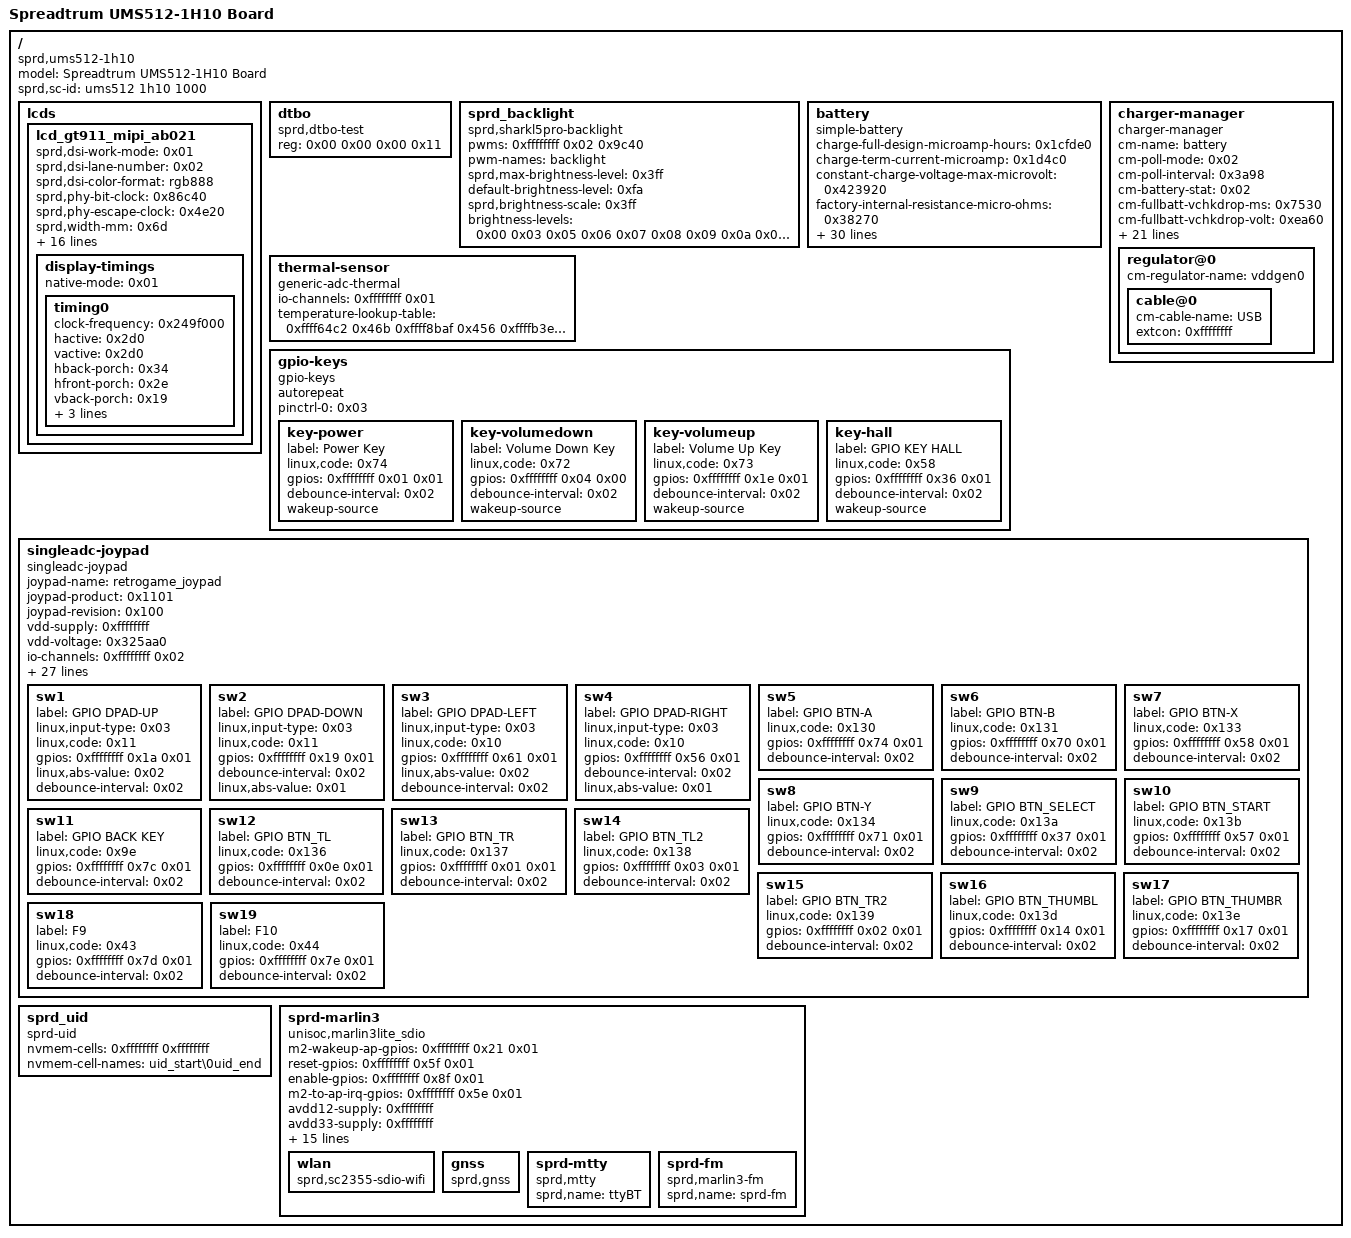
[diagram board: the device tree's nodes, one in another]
/dts-v1/;

/ {
	model = "Spreadtrum UMS512-1H10 Board";
	compatible = "sprd,ums512-1h10\0sprd,ums512";
	sprd,sc-id = "ums512 1h10 1000";

	fragment {
		target-path = "/";

		__overlay__ {
			#address-cells = <0x02>;
			#size-cells = <0x02>;

			lcds {

				lcd_gt911_mipi_ab021 {
					sprd,dsi-work-mode = <0x01>;
					sprd,dsi-lane-number = <0x02>;
					sprd,dsi-color-format = "rgb888";
					sprd,phy-bit-clock = <0x86c40>;
					sprd,phy-escape-clock = <0x4e20>;
					sprd,width-mm = <0x6d>;
					sprd,height-mm = <0x3e>;
					sprd,esd-check-enable = <0x00>;
					sprd,esd-check-mode = <0x03>;
					sprd,esd-check-period = <0x3e8>;
					sprd,esd-check-register = <0x0a>;
					sprd,esd-check-value = <0x9c>;
					sprd,reset-on-sequence = <0x01 0x32 0x00 0x32 0x01 0x78>;
					sprd,reset-off-sequence = <0x00 0x05>;
					sprd,use-dcs-write;
					sprd,initial-command = <0x29000002 0xff302900 0x2ff52 0x29000002 0xff012900 0x2e300 0x29000002 0x250a2900 0x2285f 0x29000002 0x29c22900 0x22acf 0x29000002 0x30582900 0x2379c 0x29000002 0x38a72900 0x2391f 0x29000002 0x44002900 0x2493c 0x29000002 0x59fe2900 0x25c00 0x29000002 0x80202900 0x29177 0x29000002 0x92772900 0x2a055 0x29000002 0xa1502900 0x2a358 0x29000002 0xa49c2900 0x2a702 0x29000002 0xa8012900 0x2a901 0x29000002 0xaafc2900 0x2ab28 0x29000002 0xac062900 0x2ad06 0x29000002 0xae062900 0x2af03 0x29000002 0xb0082900 0x2b126 0x29000002 0xb2282900 0x2b328 0x29000002 0xb4032900 0x2b508 0x29000002 0xb6262900 0x2b708 0x29000002 0xb8262900 0x2c000 0x29000002 0xc1002900 0x2c200 0x29000002 0xc30f2900 0x2ff30 0x29000002 0xff522900 0x2ff02 0x29000002 0xb0002900 0x2b10f 0x29000002 0xb2122900 0x2b332 0x29000002 0xb4242900 0x2b53f 0x29000002 0xb6252900 0x2b73f 0x29000002 0xb80e2900 0x2b906 0x29000002 0xba112900 0x2bb10 0x29000002 0xbc102900 0x2bd13 0x29000002 0xbe1b2900 0x2bf10 0x29000002 0xc0172900 0x2c108 0x29000002 0xd0002900 0x2d10d 0x29000002 0xd2122900 0x2d32a 0x29000002 0xd42e2900 0x2d53f 0x29000002 0xd6292900 0x2d743 0x29000002 0xd8102900 0x2d908 0x29000002 0xda132900 0x2db10 0x29000002 0xdc122900 0x2dd13 0x29000002 0xde1f2900 0x2df1a 0x29000002 0xe01f2900 0x2e10a 0x29000002 0xff302900 0x2ff52 0x29000002 0xff032900 0x20451 0x29000002 0x5c02900 0x206c0 0x29000002 0x8862900 0x20987 0x29000002 0xa842900 0x20b85 0x29000002 0x28332900 0x22933 0x29000002 0x2aeb2900 0x22bea 0x29000002 0x2ced2900 0x22dec 0x29000002 0x34812900 0x23553 0x29000002 0x37232900 0x24084 0x29000002 0x41852900 0x24282 0x29000002 0x43832900 0x24433 0x29000002 0x45ea2900 0x246e9 0x29000002 0x47332900 0x248ec 0x29000002 0x49eb2900 0x25080 0x29000002 0x51812900 0x25202 0x29000002 0x53012900 0x25433 0x29000002 0x55ee2900 0x256ed 0x29000002 0x57332900 0x258f0 0x29000002 0x59ef2900 0x28000 0x29000002 0x81012900 0x28206 0x29000002 0x83072900 0x28404 0x29000002 0x85052900 0x29203 0x29000002 0x93022900 0x29600 0x29000002 0x97012900 0x29806 0x29000002 0x99072900 0x29a04 0x29000002 0x9b052900 0x2a803 0x29000002 0xa9022900 0x2ff30 0x29000002 0xff522900 0x2ff00 0x29000002 0x36012900 0x2532c 0x5c80002 0x11000564 0x22900>;
					sprd,sleep-in-command = [13 0a 00 01 28 13 78 00 01 10];
					sprd,sleep-out-command = [13 78 00 01 11 13 32 00 01 29];
					phandle = <0x14>;

					display-timings {
						native-mode = <0x01>;

						timing0 {
							clock-frequency = <0x249f000>;
							hactive = <0x2d0>;
							vactive = <0x2d0>;
							hback-porch = <0x34>;
							hfront-porch = <0x2e>;
							vback-porch = <0x19>;
							vfront-porch = <0x1e>;
							hsync-len = <0x02>;
							vsync-len = <0x02>;
							phandle = <0x01>;
						};
					};
				};
			};

			dtbo {
				compatible = "sprd,dtbo-test";
				reg = <0x00 0x00 0x00 0x11>;
				phandle = <0x15>;
			};

			sprd_backlight {
				compatible = "sprd,sharkl5pro-backlight";
				pwms = <0xffffffff 0x02 0x9c40>;
				pwm-names = "backlight";
				sprd,max-brightness-level = <0x3ff>;
				default-brightness-level = <0xfa>;
				sprd,brightness-scale = <0x3ff>;
				brightness-levels = <0x00 0x03 0x05 0x06 0x07 0x08 0x09 0x0a 0x0c 0x0d 0x0e 0x0f 0x10 0x11 0x13 0x14 0x15 0x16 0x17 0x18 0x1a 0x1b 0x1c 0x1d 0x1e 0x1f 0x20 0x22 0x24 0x26 0x29 0x2b 0x2d 0x30 0x32 0x34 0x35 0x38 0x3a 0x3c 0x3f 0x41 0x43 0x46 0x48 0x4a 0x4d 0x4f 0x51 0x54 0x56 0x58 0x5a 0x5d 0x5f 0x61 0x64 0x66 0x68 0x6b 0x6d 0x6f 0x72 0x74 0x76 0x79 0x7b 0x7d 0x80 0x82 0x84 0x87 0x89 0x8b 0x8e 0x90 0x92 0x94 0x97 0x99 0x9b 0x9e 0xa0 0xa2 0xa5 0xa7 0xa9 0xac 0xae 0xb0 0xb3 0xb5 0xb7 0xba 0xbc 0xbe 0xc1 0xc4 0xc8 0xcb 0xce 0xd2 0xd5 0xd9 0xdc 0xe0 0xe3 0xe7 0xea 0xee 0xf1 0xf5 0xf8 0xfc 0xff 0x103 0x106 0x10a 0x10d 0x111 0x114 0x118 0x11b 0x11f 0x122 0x125 0x129 0x12c 0x130 0x133 0x137 0x13a 0x13e 0x141 0x145 0x148 0x14c 0x150 0x155 0x15a 0x15e 0x163 0x168 0x16c 0x171 0x176 0x17a 0x17f 0x183 0x188 0x18d 0x191 0x196 0x19b 0x19f 0x1a4 0x1a9 0x1ad 0x1b2 0x1b6 0x1bb 0x1c0 0x1c4 0x1c9 0x1ce 0x1d2 0x1d7 0x1dc 0x1e0 0x1e5 0x1ea 0x1ee 0x1f3 0x1f7 0x1fc 0x201 0x205 0x20b 0x211 0x217 0x21d 0x222 0x228 0x22e 0x234 0x23a 0x23f 0x245 0x24b 0x251 0x257 0x25c 0x262 0x268 0x26e 0x274 0x279 0x27f 0x285 0x28b 0x291 0x296 0x29c 0x2a2 0x2a8 0x2ae 0x2b3 0x2b9 0x2bf 0x2c5 0x2cb 0x2d0 0x2d6 0x2dc 0x2e2 0x2e8 0x2ed 0x2f4 0x2fb 0x302 0x309 0x310 0x317 0x31e 0x325 0x32c 0x333 0x33a 0x341 0x348 0x34f 0x356 0x35d 0x364 0x36b 0x372 0x379 0x380 0x386 0x38d 0x394 0x39b 0x3a2 0x3a9 0x3b0 0x3b7 0x3be 0x3c5 0x3cc 0x3d3 0x3da 0x3e1 0x3e8 0x3ef 0x3f6 0x3ff>;
				phandle = <0x07>;
			};

			battery {
				compatible = "simple-battery";
				charge-full-design-microamp-hours = <0x1cfde0>;
				charge-term-current-microamp = <0x1d4c0>;
				constant-charge-voltage-max-microvolt = <0x423920>;
				factory-internal-resistance-micro-ohms = <0x38270>;
				voltage-min-design-microvolt = <0x340850>;
				fullbatt-voltage = <0x422598>;
				fullbatt-current = <0x4e200>;
				fullbatt-track-end-vol = <0x422598>;
				fullbatt-track-end-cur = <0x50910>;
				first-calib-voltage = <0x349cc0>;
				first-calib-capacity = <0x32>;
				ocv-capacity-celsius = <0x19>;
				ocv-capacity-table-0 = <0x423150 0x64 0x40be38 0x5f 0x3feb48 0x5a 0x3f3798 0x55 0x3e9770 0x50 0x3dd038 0x4b 0x3d10d0 0x46 0x3c64f0 0x41 0x3b8648 0x3c 0x3a9800 0x37 0x39bd40 0x32 0x391930 0x2d 0x3880d8 0x28 0x380ba8 0x23 0x37c940 0x1e 0x374470 0x19 0x36daf8 0x14 0x364a70 0x0f 0x35c1b8 0x0a 0x3540d0 0x05 0x341020 0x00>;
				voltage-temp-table = <0x10b558 0x320 0xf0b90 0x352 0xd65b0 0x384 0xbd358 0x3b6 0xa5870 0x3e8 0x900b0 0x41a 0x7c830 0x44c 0x6b6c0 0x47e 0x5c490 0x4b0 0x4f1a0 0x4e2 0x43df0 0x514 0x3a1b0 0x546 0x31ce0 0x578 0x2ab98 0x5aa 0x249f0 0x5dc 0x1f7e8 0x60e 0x1b198 0x640 0x17700 0x672>;
				capacity-temp-table = <0x2d 0x64 0x19 0x64 0x0a 0x62 0x00 0x5d 0xfffffff6 0x55 0xffffffec 0x40>;
				resistance-temp-table = <0x2d 0x62 0x19 0x61 0x0a 0x61 0x00 0x61 0xfffffff6 0x62 0xffffffec 0x62>;
				charge-sdp-current-microamp = <0x7a120 0x7a120>;
				charge-dcp-current-microamp = <0x1e8480 0x2dc6c0>;
				charge-cdp-current-microamp = <0x1e8480 0x1e8480>;
				charge-unknown-current-microamp = <0x118c30 0x118c30>;
				dcp-jeita-temp-table = <0x3e8 0x406 0x00 0x423920 0x47e 0x49c 0xf4240 0x423920 0x5aa 0x58c 0x1e8480 0x423920 0x640 0x622 0xaae60 0x3e8fa0>;
				sdp-jeita-temp-table = <0x3e8 0x406 0x00 0x423920 0x47e 0x49c 0x7a120 0x423920 0x5aa 0x58c 0x1e8480 0x423920 0x640 0x622 0x7a120 0x3e8fa0>;
				cdp-jeita-temp-table = <0x3e8 0x406 0x00 0x423920 0x47e 0x49c 0x16e360 0x423920 0x5aa 0x58c 0x1e8480 0x423920 0x640 0x622 0xaae60 0x3e8fa0>;
				unknown-jeita-temp-table = <0x3e8 0x406 0x00 0x423920 0x47e 0x49c 0x7a120 0x423920 0x5aa 0x58c 0x7a120 0x423920 0x640 0x622 0x7a120 0x3e8fa0>;
				force-jeita-status = <0x02>;
				phandle = <0x02>;
			};

			charger-manager {
				compatible = "charger-manager";
				cm-name = "battery";
				cm-poll-mode = <0x02>;
				cm-poll-interval = <0x3a98>;
				cm-battery-stat = <0x02>;
				cm-fullbatt-vchkdrop-ms = <0x7530>;
				cm-fullbatt-vchkdrop-volt = <0xea60>;
				cm-fullbatt-capacity = <0x64>;
				cm-fullbatt-soc = <0x64>;
				cm-num-chargers = <0x01>;
				cm-chargers = "aw32257-charger";
				cm-fuel-gauge = "sc27xx-fgu";
				cm-battery-cold = <0xc8>;
				cm-battery-cold-in-minus;
				cm-battery-hot = <0x320>;
				cm-battery-temp-diff = <0x64>;
				cm-charging-max = <0x1499700>;
				cm-discharging-max = <0x2932e0>;
				cm-wdt-interval = <0x3c>;
				cm-shutdown-voltage = <0x2f4d60>;
				cm-tickle-time-out = <0x12c>;
				cm-one-cap-time = <0x1e>;
				cm-thermal-zone = "board-thmzone";
				cm-charge-voltage-max = <0x632ea0>;
				cm-charge-voltage-drop = <0xaae60>;
				monitored-battery = <0x02>;
				cm-cap-remap-table = <0x01 0x02 0x03 0x02 0x03 0x02 0x62 0x63 0x02 0x63 0x64 0x03>;

				regulator@0 {
					cm-regulator-name = "vddgen0";

					cable@0 {
						cm-cable-name = "USB";
						extcon = <0xffffffff>;
					};
				};
			};

			thermal-sensor {
				compatible = "generic-adc-thermal";
				#thermal-sensor-cells = <0x00>;
				io-channels = <0xffffffff 0x01>;
				io-channel-names = "sensor-channel";
				temperature-lookup-table = <0xffff64c2 0x46b 0xffff8baf 0x456 0xffffb3e8 0x432 0xffffedb9 0x3d7 0x277e 0x346 0x60e5 0x28e 0xaf7a 0x19d 0xd677 0x13c 0xfd7f 0xee 0x12484 0xb2 0x14b93 0x85 0x172a3 0x64 0x199b0 0x4b 0x1c0c9 0x39 0x1e7c8 0x2b>;
				phandle = <0x04>;
			};

			gpio-keys {
				compatible = "gpio-keys";
				autorepeat;
				pinctrl-names = "gpio_124";
				pinctrl-0 = <0x03>;

				key-power {
					label = "Power Key";
					linux,code = <0x74>;
					gpios = <0xffffffff 0x01 0x01>;
					debounce-interval = <0x02>;
					wakeup-source;
				};

				key-volumedown {
					label = "Volume Down Key";
					linux,code = <0x72>;
					gpios = <0xffffffff 0x04 0x00>;
					debounce-interval = <0x02>;
					wakeup-source;
				};

				key-volumeup {
					label = "Volume Up Key";
					linux,code = <0x73>;
					gpios = <0xffffffff 0x1e 0x01>;
					debounce-interval = <0x02>;
					wakeup-source;
				};

				key-hall {
					label = "GPIO KEY HALL";
					linux,code = <0x58>;
					gpios = <0xffffffff 0x36 0x01>;
					debounce-interval = <0x02>;
					wakeup-source;
				};
			};

			singleadc-joypad {
				compatible = "singleadc-joypad";
				joypad-name = "retrogame_joypad";
				joypad-product = <0x1101>;
				joypad-revision = <0x100>;
				vdd-supply = <0xffffffff>;
				vdd-voltage = <0x325aa0>;
				status = "okay";
				io-channels = <0xffffffff 0x02>;
				io-channel-names = "joypad_adc";
				amux-count = <0x06>;
				amux-a-gpios = <0xffffffff 0x76 0x01>;
				amux-b-gpios = <0xffffffff 0x13 0x01>;
				amux-en-gpios = <0xffffffff 0x0f 0x01>;
				adc-power-ctl1 = <0xffffffff 0x25 0x01>;
				adc-power-ctl2 = <0xffffffff 0x60 0x01>;
				adc-power-ctl3 = <0xffffffff 0x16 0x01>;
				adc-power-ctl4 = <0xffffffff 0x18 0x01>;
				adc-power-en-gpios = <0xffffffff 0x10 0x01>;
				fan-power-en-gpios = <0xffffffff 0x8b 0x01>;
				button-adc-scale = <0x01>;
				button-adc-deadzone = <0x5dc>;
				button-adc-fuzz = <0x40>;
				button-adc-flat = <0x40>;
				abs_x-p-tuning = <0x64>;
				abs_x-n-tuning = <0x64>;
				abs_y-p-tuning = <0x64>;
				abs_y-n-tuning = <0x64>;
				abs_rx-p-tuning = <0x64>;
				abs_rx-n-tuning = <0x64>;
				abs_ry-p-tuning = <0x64>;
				abs_ry-n-tuning = <0x64>;
				abs_z-p-tuning = <0xc8>;
				abs_z-n-tuning = <0xc8>;
				abs_rz-p-tuning = <0xc8>;
				abs_rz-n-tuning = <0xc8>;
				poll-interval = <0x04>;

				sw1 {
					label = "GPIO DPAD-UP";
					linux,input-type = <0x03>;
					linux,code = <0x11>;
					gpios = <0xffffffff 0x1a 0x01>;
					linux,abs-value = <0x02>;
					debounce-interval = <0x02>;
				};

				sw2 {
					label = "GPIO DPAD-DOWN";
					linux,input-type = <0x03>;
					linux,code = <0x11>;
					gpios = <0xffffffff 0x19 0x01>;
					debounce-interval = <0x02>;
					linux,abs-value = <0x01>;
				};

				sw3 {
					label = "GPIO DPAD-LEFT";
					linux,input-type = <0x03>;
					linux,code = <0x10>;
					gpios = <0xffffffff 0x61 0x01>;
					linux,abs-value = <0x02>;
					debounce-interval = <0x02>;
				};

				sw4 {
					label = "GPIO DPAD-RIGHT";
					linux,input-type = <0x03>;
					linux,code = <0x10>;
					gpios = <0xffffffff 0x56 0x01>;
					debounce-interval = <0x02>;
					linux,abs-value = <0x01>;
				};

				sw5 {
					label = "GPIO BTN-A";
					linux,code = <0x130>;
					gpios = <0xffffffff 0x74 0x01>;
					debounce-interval = <0x02>;
				};

				sw6 {
					label = "GPIO BTN-B";
					linux,code = <0x131>;
					gpios = <0xffffffff 0x70 0x01>;
					debounce-interval = <0x02>;
				};

				sw7 {
					label = "GPIO BTN-X";
					linux,code = <0x133>;
					gpios = <0xffffffff 0x58 0x01>;
					debounce-interval = <0x02>;
				};

				sw8 {
					label = "GPIO BTN-Y";
					linux,code = <0x134>;
					gpios = <0xffffffff 0x71 0x01>;
					debounce-interval = <0x02>;
				};

				sw9 {
					label = "GPIO BTN_SELECT";
					linux,code = <0x13a>;
					gpios = <0xffffffff 0x37 0x01>;
					debounce-interval = <0x02>;
				};

				sw10 {
					label = "GPIO BTN_START";
					linux,code = <0x13b>;
					gpios = <0xffffffff 0x57 0x01>;
					debounce-interval = <0x02>;
				};

				sw11 {
					label = "GPIO BACK KEY";
					linux,code = <0x9e>;
					gpios = <0xffffffff 0x7c 0x01>;
					debounce-interval = <0x02>;
				};

				sw12 {
					label = "GPIO BTN_TL";
					linux,code = <0x136>;
					gpios = <0xffffffff 0x0e 0x01>;
					debounce-interval = <0x02>;
				};

				sw13 {
					label = "GPIO BTN_TR";
					linux,code = <0x137>;
					gpios = <0xffffffff 0x01 0x01>;
					debounce-interval = <0x02>;
				};

				sw14 {
					label = "GPIO BTN_TL2";
					linux,code = <0x138>;
					gpios = <0xffffffff 0x03 0x01>;
					debounce-interval = <0x02>;
				};

				sw15 {
					label = "GPIO BTN_TR2";
					linux,code = <0x139>;
					gpios = <0xffffffff 0x02 0x01>;
					debounce-interval = <0x02>;
				};

				sw16 {
					label = "GPIO BTN_THUMBL";
					linux,code = <0x13d>;
					gpios = <0xffffffff 0x14 0x01>;
					debounce-interval = <0x02>;
				};

				sw17 {
					label = "GPIO BTN_THUMBR";
					linux,code = <0x13e>;
					gpios = <0xffffffff 0x17 0x01>;
					debounce-interval = <0x02>;
				};

				sw18 {
					label = "F9";
					linux,code = <0x43>;
					gpios = <0xffffffff 0x7d 0x01>;
					debounce-interval = <0x02>;
				};

				sw19 {
					label = "F10";
					linux,code = <0x44>;
					gpios = <0xffffffff 0x7e 0x01>;
					debounce-interval = <0x02>;
				};
			};

			sprd_uid {
				compatible = "sprd-uid";
				nvmem-cells = <0xffffffff 0xffffffff>;
				nvmem-cell-names = "uid_start\0uid_end";
			};

			sprd-marlin3 {
				compatible = "unisoc,marlin3lite_sdio";
				m2-wakeup-ap-gpios = <0xffffffff 0x21 0x01>;
				reset-gpios = <0xffffffff 0x5f 0x01>;
				enable-gpios = <0xffffffff 0x8f 0x01>;
				m2-to-ap-irq-gpios = <0xffffffff 0x5e 0x01>;
				avdd12-supply = <0xffffffff>;
				avdd33-supply = <0xffffffff>;
				dcxo18-supply = <0xffffffff>;
				clock-names = "clk_32k\0source\0enable";
				clocks = <0xffffffff 0x02 0xffffffff 0xffffffff 0x03>;
				extcon = <0xffffffff>;
				sdhci-name = <0xffffffff>;
				sprd,btwf-file-name = "/dev/block/platform/soc/soc:ap-apb/71400000.sdio/by-name/wcnmodem";
				sprd,gnss-file-name = "/vendor/firmware/gnssmodem.bin";
				adma-tx;
				adma-rx;
				avdd12-parent-bound-chip = <0x1a4c 0x01 0x00 0x01>;
				avdd12-bound-wbreq = <0x1ac8 0x1000 0x00 0x1000>;
				avdd33-bound-wbreq = <0x1acc 0x04 0x00 0x04>;
				phandle = <0x16>;

				wlan {
					compatible = "sprd,sc2355-sdio-wifi";
				};

				gnss {
					compatible = "sprd,gnss";
				};

				sprd-mtty {
					compatible = "sprd,mtty";
					sprd,name = "ttyBT";
				};

				sprd-fm {
					compatible = "sprd,marlin3-fm";
					sprd,name = "sprd-fm";
				};
			};
		};
	};

	fragment@0 {
		target = <0xffffffff>;

		__overlay__ {

			board-thmzone {
				polling-delay-passive = <0x00>;
				polling-delay = <0x00>;
				thermal-sensors = <0x04>;
				phandle = <0x17>;
			};
		};
	};

	fragment@1 {
		target = <0xffffffff>;

		__overlay__ {
			#address-cells = <0x01>;
			#size-cells = <0x00>;

			heap@1 {
				reg = <0x01>;
				label = "carveout_mm";
				type = <0x02>;
				memory-region = <0x05>;
			};

			heap@2 {
				reg = <0x02>;
				label = "carveout_fd";
				type = <0x02>;
				memory-region = <0x06>;
			};
		};
	};

	fragment@2 {
		target = <0xffffffff>;

		__overlay__ {
			#address-cells = <0x01>;
			#size-cells = <0x00>;
			status = "okay";
			clock-frequency = <0x61a80>;
		};
	};

	fragment@3 {
		target = <0xffffffff>;

		__overlay__ {
			#address-cells = <0x01>;
			#size-cells = <0x00>;
			status = "okay";
			clock-frequency = <0x61a80>;
		};
	};

	fragment@4 {
		target = <0xffffffff>;

		__overlay__ {
			status = "okay";
			#address-cells = <0x01>;
			#size-cells = <0x00>;
			clock-frequency = <0x61a80>;

			aw87xxx_pa@58 {
				compatible = "awinic,aw87xxx_pa";
				reg = <0x58>;
				dev_index = <0x00>;
				status = "okay";
			};

			aw87xxx_pa@59 {
				compatible = "awinic,aw87xxx_pa";
				reg = <0x59>;
				dev_index = <0x01>;
				status = "okay";
			};
		};
	};

	fragment@5 {
		target = <0xffffffff>;

		__overlay__ {
			#address-cells = <0x01>;
			#size-cells = <0x00>;
			status = "okay";

			touchscreen@14 {
				compatible = "goodix,gt9xx";
				status = "okay";
				reg = <0x14>;
				vcc-gpios = <0xffffffff 0x10 0x00>;
				irq-gpios = <0xffffffff 0x90 0x00>;
				reset-gpios = <0xffffffff 0x91 0x00>;
				touchscreen-max-id = <0x0b>;
				touchscreen-size-x = <0x2d0>;
				touchscreen-size-y = <0x2d0>;
				touchscreen-max-w = <0x200>;
				touchscreen-max-p = <0x200>;
				irq-flags = <0x02>;
				goodix,slide-wakeup = <0x00>;
				goodix,type-a-report = <0x00>;
				goodix,driver-send-cfg = <0x01>;
				goodix,resume-in-workqueue = <0x00>;
				goodix,int-sync = <0x01>;
				goodix,swap-x2y = <0x00>;
				goodix,esd-protect = <0x01>;
				goodix,auto-update-cfg = <0x00>;
				goodix,power-off-sleep = <0x00>;
				goodix,pen-suppress-finger = <0x00>;
				goodix,cfg-group0 = [5c d0 02 d0 02 05 3d 00 11 0f 28 0f 50 32 03 05 00 00 00 00 00 00 00 18 1a 1e 14 87 27 0e 28 2a f4 0a 00 00 00 9b 03 10 00 01 00 00 00 03 64 32 00 00 00 14 46 94 d5 02 07 00 00 04 da 16 00 aa 1d 00 89 25 00 6d 30 00 57 3e 00 57 00 00 00 00 00 00 00 00 00 00 00 00 00 00 00 00 00 00 00 00 00 00 00 00 00 00 00 00 00 00 00 00 00 00 00 00 1c 1a 18 16 14 12 10 0e 0c 0a 08 06 04 02 ff ff ff ff ff ff ff ff ff ff ff ff ff ff ff ff 00 02 04 06 08 0a 0c 1d 1e 1f 20 21 22 24 ff ff ff ff ff ff ff ff ff ff ff ff ff ff ff ff ff ff ff ff ff ff ff ff ff ff ff ff b6 01];
			};
		};
	};

	fragment@6 {
		target = <0xffffffff>;

		__overlay__ {
			#address-cells = <0x01>;
			#size-cells = <0x00>;

			charger@6a {
				compatible = "aw32257-charger";
				reg = <0x6a>;
				phys = <0xffffffff>;
				monitored-battery = <0x02>;
				extcon = <0xffffffff>;
				ti,current-limit = <0x1e8480>;
				ti,weak-battery-voltage = <0xd48>;
				ti,battery-regulation-voltage = <0x1068>;
				ti,charge-current = <0x1e8480>;
				ti,termination-current = <0x1e8480>;
				ti,resistor-sense = <0x21>;
				phandle = <0x18>;

				otg-vbus {
					regulator-name = "vddvbus";
					phandle = <0x09>;
				};
			};
		};
	};

	fragment@7 {
		target = <0xffffffff>;

		__overlay__ {
			status = "okay";
			clock-frequency = <0xf4240>;
		};
	};

	fragment@8 {
		target = <0xffffffff>;

		__overlay__ {
			sprd-scene = "boost\0lcdon\0lcdoff\0camlow\0camhigh\0camveryhigh\0faceid\0top";
			sprd-freq = <0x400 0x400 0x100 0x180 0x200 0xbacd 0x400 0xbacd>;
		};
	};

	fragment@9 {
		target = <0xffffffff>;

		__overlay__ {
			sprd,backlight = <0x07>;
			sprd,surface-width = <0x2d0>;
			sprd,surface-height = <0x2d0>;
			reset-gpio = <0xffffffff 0x32 0x00>;
			avdd-gpio = <0xffffffff 0x0f 0x00>;
			avee-gpio = <0xffffffff 0x8a 0x00>;
		};
	};

	fragment@10 {
		target = <0xffffffff>;

		__overlay__ {
			sprd,backlight = <0x07>;
			sprd,logo-memory = <0x08>;
		};
	};

	fragment@11 {
		target = <0xffffffff>;

		__overlay__ {
			bootargs_ext = "androidboot.hardware=ums512_1h10";
		};
	};

	fragment@12 {
		target = <0xffffffff>;

		__overlay__ {
			#address-cells = <0x02>;
			#size-cells = <0x02>;

			logobuffer@9e000000 {
				reg = <0x00 0x9e000000 0x00 0x9e4000>;
				phandle = <0x08>;
			};

			widevine@e3800000 {
				reg = <0x00 0xe3800000 0x00 0xc800000>;
				phandle = <0x05>;
			};

			faceid-mem@fd270000 {
				reg = <0x00 0xfd270000 0x00 0x500000>;
				phandle = <0x06>;
			};

			vdsp-mem@fd770000 {
				reg = <0x00 0xfd770000 0x00 0x2800000>;
				phandle = <0x19>;
			};
		};
	};

	fragment@13 {
		target = <0xffffffff>;

		__overlay__ {
			sprd,hw-channels = <0x02 0x18cc 0x03 0x18cc 0x0d 0x1854 0x0f 0x1874 0x11 0x1844 0x13 0x1844 0x15 0x1864 0x1e 0x1820 0x20 0x197c 0x21 0x1988 0x23 0x19b8 0x27 0x19ac>;
		};
	};

	fragment@14 {
		target = <0xffffffff>;

		__overlay__ {
			regulator-always-on;
		};
	};

	fragment@15 {
		target = <0xffffffff>;

		__overlay__ {
			vdd-supply = <0xffffffff>;
			extcon = <0xffffffff>;
			status = "okay";
		};
	};

	fragment@16 {
		target = <0xffffffff>;

		__overlay__ {
			extcon = <0xffffffff 0xffffffff>;
			status = "okay";
			vbus-supply = <0x09>;
		};
	};

	fragment@17 {
		target = <0xffffffff>;

		__overlay__ {
			monitored-battery = <0x02>;
			sprd,calib-resistance-micro-ohms = <0x2710>;
			sprd,comp-resistance-mohm = <0x14>;
			fgu-capacity-track;
			phys = <0xffffffff>;
		};
	};

	fragment@18 {
		target = <0xffffffff>;

		__overlay__ {
			cd-gpios = <0xffffffff 0x13 0x01>;
			sprd,phy-delay-sd-uhs-sdr104 = <0x7f 0x73 0x72 0x72>;
			sprd,phy-delay-sd-uhs-sdr50 = <0x6e 0x7f 0x01 0x01>;
			sprd,phy-delay-sd-highspeed = <0x7f 0x1a 0x9a 0x9a>;
			sprd,phy-delay-legacy = <0x7f 0x1a 0x9a 0x9a>;
			vmmc-supply = <0xffffffff>;
			vqmmc-supply = <0xffffffff>;
			sd-uhs-sdr104;
			sd-uhs-sdr50;
			sprd,name = "sdio_sd";
			status = "okay";
		};
	};

	fragment@19 {
		target = <0xffffffff>;

		__overlay__ {
			sprd,phy-delay-sd-uhs-sdr104 = <0x7f 0x76 0x69 0x69>;
			sprd,phy-delay-sd-uhs-sdr50 = <0x7f 0xf7 0xf5 0xf5>;
			sd-uhs-sdr104;
			sd-uhs-sdr50;
		};
	};

	fragment@20 {
		target = <0xffffffff>;

		__overlay__ {
			sprd,phy-delay-mmc-hs400es = <0x40 0x7f 0x2d 0x2d>;
			sprd,phy-delay-mmc-hs400 = <0x3f 0xdf 0x2f 0x2f>;
			sprd,phy-delay-mmc-hs200 = <0x7f 0xde 0xd4 0xd4>;
			sprd,phy-delay-mmc-ddr52 = <0x3e 0x37 0x24 0x24>;
			sprd,phy-delay-mmc-highspeed = <0x60 0xb7 0x34 0x34>;
			vmmc-supply = <0xffffffff>;
			voltage-ranges = <0xbb8 0xbb8>;
			bus-width = <0x08>;
			non-removable;
			cap-mmc-hw-reset;
			mmc-hs400-enhanced-strobe;
			mmc-hs400-1_8v;
			mmc-hs200-1_8v;
			mmc-ddr-1_8v;
			no-sdio;
			no-sd;
			status = "okay";
		};
	};

	fragment@21 {
		target = <0xffffffff>;

		__overlay__ {
			pinctrl-names = "gpio_121\0gpio_122\0gpio_123\0gpio_124\0gpio_125\0gpio_126\0gpio_144\0gpio_145\0gpio_146\0gpio_147\0gpio_16";
			pinctrl-0 = <0x0a>;
			pinctrl-1 = <0x0b>;
			pinctrl-2 = <0x0c>;
			pinctrl-3 = <0x03>;
			pinctrl-4 = <0x0d>;
			pinctrl-5 = <0x0e>;
			pinctrl-6 = <0x0f>;
			pinctrl-7 = <0x10>;
			pinctrl-8 = <0x11>;
			pinctrl-9 = <0x12>;
			pinctrl-10 = <0x13>;

			keyout0 {
				pins = "SHARKL5PRO_KEYOUT0";
				function = "func4";
				phandle = <0x0a>;
			};

			keyout1 {
				pins = "SHARKL5PRO_KEYOUT1";
				function = "func4";
				phandle = <0x0b>;
			};

			keyout2 {
				pins = "SHARKL5PRO_KEYOUT2";
				function = "func4";
				phandle = <0x0c>;
			};

			keyin0 {
				pins = "SHARKL5PRO_KEYIN0";
				function = "func4";
				phandle = <0x03>;
			};

			keyin1 {
				pins = "SHARKL5PRO_KEYIN1";
				function = "func4";
				phandle = <0x0d>;
			};

			keyin2 {
				pins = "SHARKL5PRO_KEYIN2";
				function = "func4";
				phandle = <0x0e>;
			};

			extint0 {
				pins = "SHARKL5PRO_EXTINT0";
				function = "func4";
				phandle = <0x0f>;
			};

			extint1 {
				pins = "SHARKL5PRO_EXTINT1";
				function = "func4";
				phandle = <0x10>;
			};

			scl3 {
				pins = "SHARKL5PRO_SCL3";
				function = "func4";
				phandle = <0x12>;
			};

			sda3 {
				pins = "SHARKL5PRO_SDA3";
				function = "func4";
				phandle = <0x11>;
			};

			rffe1_sda {
				pins = "SHARKL5PRO_RFFE1_SDA";
				function = "func4";
				phandle = <0x13>;
			};
		};
	};

	fragment@22 {
		target = <0xffffffff>;

		__overlay__ {
			status = "okay";
			sprd,spk-ext-pa-info = <0x00 0x00 0x04 0x00>;
			sprd,spk-ext-pa-gpio = <0xffffffff 0x09 0x00>;
		};
	};

	fragment@23 {
		target = <0xffffffff>;

		__overlay__ {
			status = "okay";
			#address-cells = <0x01>;
			#size-cells = <0x00>;

			spi_mcu_joy@0 {
				compatible = "sprd,spi-mcu-joy";
				reg = <0x00>;
				spi-max-frequency = <0xf4240>;
				mcu-pwr-gpios = <0xffffffff 0x24 0x00>;
				sim-vdd-supply = <0xffffffff>;
				buf-len = <0x40>;
			};
		};
	};

	__symbols__ {
		lcd_gt911_mipi_ab021 = "/fragment/__overlay__/lcds/lcd_gt911_mipi_ab021";
		timing0 = "/fragment/__overlay__/lcds/lcd_gt911_mipi_ab021/display-timings/timing0";
		dtbo = "/fragment/__overlay__/dtbo";
		pwm_backlight = "/fragment/__overlay__/sprd_backlight";
		bat = "/fragment/__overlay__/battery";
		tboard_thermistor = "/fragment/__overlay__/thermal-sensor";
		sprd_marlin3 = "/fragment/__overlay__/sprd-marlin3";
		bd_thmzone = "/fragment@0/__overlay__/board-thmzone";
		aw32257_chg = "/fragment@6/__overlay__/charger@6a";
		vddvbus = "/fragment@6/__overlay__/charger@6a/otg-vbus";
		logo_reserved = "/fragment@12/__overlay__/logobuffer@9e000000";
		widevine_reserved = "/fragment@12/__overlay__/widevine@e3800000";
		fd_reserved = "/fragment@12/__overlay__/faceid-mem@fd270000";
		vdsp_reserved = "/fragment@12/__overlay__/vdsp-mem@fd770000";
		gpio_121 = "/fragment@21/__overlay__/keyout0";
		gpio_122 = "/fragment@21/__overlay__/keyout1";
		gpio_123 = "/fragment@21/__overlay__/keyout2";
		gpio_124 = "/fragment@21/__overlay__/keyin0";
		gpio_125 = "/fragment@21/__overlay__/keyin1";
		gpio_126 = "/fragment@21/__overlay__/keyin2";
		gpio_144 = "/fragment@21/__overlay__/extint0";
		gpio_145 = "/fragment@21/__overlay__/extint1";
		gpio_147 = "/fragment@21/__overlay__/scl3";
		gpio_146 = "/fragment@21/__overlay__/sda3";
		gpio_16 = "/fragment@21/__overlay__/rffe1_sda";
	};

	__fixups__ {
		pwms = "/fragment/__overlay__/sprd_backlight:pwms:0";
		pmic_typec = "/fragment/__overlay__/charger-manager/regulator@0/cable@0:extcon:0\0/fragment@16/__overlay__:extcon:4";
		pmic_adc = "/fragment/__overlay__/thermal-sensor:io-channels:0\0/fragment/__overlay__/singleadc-joypad:io-channels:0";
		pmic_eic = "/fragment/__overlay__/gpio-keys/key-power:gpios:0\0/fragment/__overlay__/gpio-keys/key-volumedown:gpios:0";
		ap_gpio = "/fragment/__overlay__/gpio-keys/key-volumeup:gpios:0\0/fragment/__overlay__/gpio-keys/key-hall:gpios:0\0/fragment/__overlay__/singleadc-joypad:amux-a-gpios:0\0/fragment/__overlay__/singleadc-joypad:amux-b-gpios:0\0/fragment/__overlay__/singleadc-joypad:amux-en-gpios:0\0/fragment/__overlay__/singleadc-joypad:adc-power-ctl1:0\0/fragment/__overlay__/singleadc-joypad:adc-power-ctl2:0\0/fragment/__overlay__/singleadc-joypad:adc-power-ctl3:0\0/fragment/__overlay__/singleadc-joypad:adc-power-ctl4:0\0/fragment/__overlay__/singleadc-joypad:adc-power-en-gpios:0\0/fragment/__overlay__/singleadc-joypad:fan-power-en-gpios:0\0/fragment/__overlay__/singleadc-joypad/sw1:gpios:0\0/fragment/__overlay__/singleadc-joypad/sw2:gpios:0\0/fragment/__overlay__/singleadc-joypad/sw3:gpios:0\0/fragment/__overlay__/singleadc-joypad/sw4:gpios:0\0/fragment/__overlay__/singleadc-joypad/sw5:gpios:0\0/fragment/__overlay__/singleadc-joypad/sw6:gpios:0\0/fragment/__overlay__/singleadc-joypad/sw7:gpios:0\0/fragment/__overlay__/singleadc-joypad/sw8:gpios:0\0/fragment/__overlay__/singleadc-joypad/sw9:gpios:0\0/fragment/__overlay__/singleadc-joypad/sw10:gpios:0\0/fragment/__overlay__/singleadc-joypad/sw11:gpios:0\0/fragment/__overlay__/singleadc-joypad/sw12:gpios:0\0/fragment/__overlay__/singleadc-joypad/sw13:gpios:0\0/fragment/__overlay__/singleadc-joypad/sw14:gpios:0\0/fragment/__overlay__/singleadc-joypad/sw15:gpios:0\0/fragment/__overlay__/singleadc-joypad/sw16:gpios:0\0/fragment/__overlay__/singleadc-joypad/sw17:gpios:0\0/fragment/__overlay__/singleadc-joypad/sw18:gpios:0\0/fragment/__overlay__/singleadc-joypad/sw19:gpios:0\0/fragment/__overlay__/sprd-marlin3:m2-wakeup-ap-gpios:0\0/fragment/__overlay__/sprd-marlin3:reset-gpios:0\0/fragment/__overlay__/sprd-marlin3:enable-gpios:0\0/fragment/__overlay__/sprd-marlin3:m2-to-ap-irq-gpios:0\0/fragment@5/__overlay__/touchscreen@14:vcc-gpios:0\0/fragment@5/__overlay__/touchscreen@14:irq-gpios:0\0/fragment@5/__overlay__/touchscreen@14:reset-gpios:0\0/fragment@9/__overlay__:reset-gpio:0\0/fragment@9/__overlay__:avdd-gpio:0\0/fragment@9/__overlay__:avee-gpio:0\0/fragment@22/__overlay__:sprd,spk-ext-pa-gpio:0\0/fragment@23/__overlay__/spi_mcu_joy@0:mcu-pwr-gpios:0";
		vddldo1 = "/fragment/__overlay__/singleadc-joypad:vdd-supply:0";
		uid_start = "/fragment/__overlay__/sprd_uid:nvmem-cells:0";
		uid_end = "/fragment/__overlay__/sprd_uid:nvmem-cells:4";
		vddwcn = "/fragment/__overlay__/sprd-marlin3:avdd12-supply:0";
		vddwifipa = "/fragment/__overlay__/sprd-marlin3:avdd33-supply:0";
		vddsim2 = "/fragment/__overlay__/sprd-marlin3:dcxo18-supply:0\0/fragment@23/__overlay__/spi_mcu_joy@0:sim-vdd-supply:0";
		aon_clk = "/fragment/__overlay__/sprd-marlin3:clocks:0";
		ext_32k = "/fragment/__overlay__/sprd-marlin3:clocks:8";
		aonapb_gate = "/fragment/__overlay__/sprd-marlin3:clocks:12";
		sdio1 = "/fragment/__overlay__/sprd-marlin3:extcon:0\0/fragment/__overlay__/sprd-marlin3:sdhci-name:0\0/fragment@19:target:0";
		thm_zone = "/fragment@0:target:0";
		ion = "/fragment@1:target:0";
		i2c0 = "/fragment@2:target:0";
		i2c1 = "/fragment@3:target:0";
		i2c2 = "/fragment@4:target:0";
		i2c3 = "/fragment@5:target:0";
		i2c4 = "/fragment@6:target:0";
		hsphy = "/fragment@6/__overlay__/charger@6a:phys:0\0/fragment@15:target:0\0/fragment@17/__overlay__:phys:0";
		extcon_gpio = "/fragment@6/__overlay__/charger@6a:extcon:0\0/fragment@15/__overlay__:extcon:0\0/fragment@16/__overlay__:extcon:0";
		aon_i2c0 = "/fragment@7:target:0";
		ddr_dfs = "/fragment@8:target:0";
		panel = "/fragment@9:target:0";
		dpu = "/fragment@10:target:0";
		chosen = "/fragment@11:target:0";
		reserved_memory = "/fragment@12:target:0";
		adi_bus = "/fragment@13:target:0";
		vddldo0 = "/fragment@14:target:0";
		vddusb33 = "/fragment@15/__overlay__:vdd-supply:0";
		usb = "/fragment@16:target:0";
		pmic_fgu = "/fragment@17:target:0";
		sdio0 = "/fragment@18:target:0";
		eic_sync = "/fragment@18/__overlay__:cd-gpios:0";
		vddsdcore = "/fragment@18/__overlay__:vmmc-supply:0";
		vddsdio = "/fragment@18/__overlay__:vqmmc-supply:0";
		sdio3 = "/fragment@20:target:0";
		vddemmccore = "/fragment@20/__overlay__:vmmc-supply:0";
		pin_controller = "/fragment@21:target:0";
		sound_vbc_v4_sprd_codec = "/fragment@22:target:0";
		spi0 = "/fragment@23:target:0";
	};

	__local_fixups__ {

		fragment {

			__overlay__ {

				lcds {

					lcd_gt911_mipi_ab021 {

						display-timings {
							native-mode = <0x00>;
						};
					};
				};

				charger-manager {
					monitored-battery = <0x00>;
				};

				gpio-keys {
					pinctrl-0 = <0x00>;
				};
			};
		};

		fragment@0 {

			__overlay__ {

				board-thmzone {
					thermal-sensors = <0x00>;
				};
			};
		};

		fragment@1 {

			__overlay__ {

				heap@1 {
					memory-region = <0x00>;
				};

				heap@2 {
					memory-region = <0x00>;
				};
			};
		};

		fragment@6 {

			__overlay__ {

				charger@6a {
					monitored-battery = <0x00>;
				};
			};
		};

		fragment@9 {

			__overlay__ {
				sprd,backlight = <0x00>;
			};
		};

		fragment@10 {

			__overlay__ {
				sprd,backlight = <0x00>;
				sprd,logo-memory = <0x00>;
			};
		};

		fragment@16 {

			__overlay__ {
				vbus-supply = <0x00>;
			};
		};

		fragment@17 {

			__overlay__ {
				monitored-battery = <0x00>;
			};
		};

		fragment@21 {

			__overlay__ {
				pinctrl-0 = <0x00>;
				pinctrl-1 = <0x00>;
				pinctrl-2 = <0x00>;
				pinctrl-3 = <0x00>;
				pinctrl-4 = <0x00>;
				pinctrl-5 = <0x00>;
				pinctrl-6 = <0x00>;
				pinctrl-7 = <0x00>;
				pinctrl-8 = <0x00>;
				pinctrl-9 = <0x00>;
				pinctrl-10 = <0x00>;
			};
		};
	};
};
